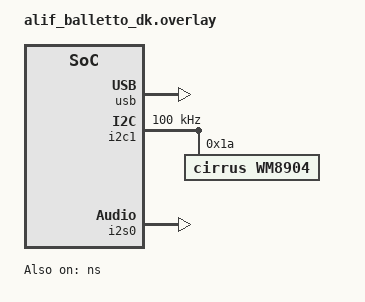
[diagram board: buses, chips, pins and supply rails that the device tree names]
/*
 * Copyright (c) 2026 Alif Semiconductor.
 * SPDX-License-Identifier: Apache-2.0
 */


#include <dt-bindings/misc/alif_aipm_common.h>

&aipm_run_default {
	phy-pwr-gating = <ALIF_PHY_GATE_USB_MASK>;
};

ns: &ns {
	status = "okay";
};

zephyr_udc0: &usb {
	status = "okay";
};

&i2c1 {
	clock-frequency = <I2C_BITRATE_STANDARD>;
	status = "okay";

	wm8904: wm8904@1a {
		compatible = "cirrus,wm8904";
		reg = <0x1a>;
		status = "okay";
	};
};

i2s_tx: &i2s0 {
	status = "okay";
};

&pinctrl_i2s0 {
	group0 {
		pinmux = <PIN_P2_4__I2S0_SDI_B>,
			 <PIN_P2_5__I2S0_SDO_B>,
			 <PIN_P1_7__I2S0_WS_A>,
			 <PIN_P1_6__I2S0_SCLK_A>;
	};
};

&uac2_headphones {
	high-speed;
};


/ {
	aliases {
		audio-codec = &wm8904;
	};
};
